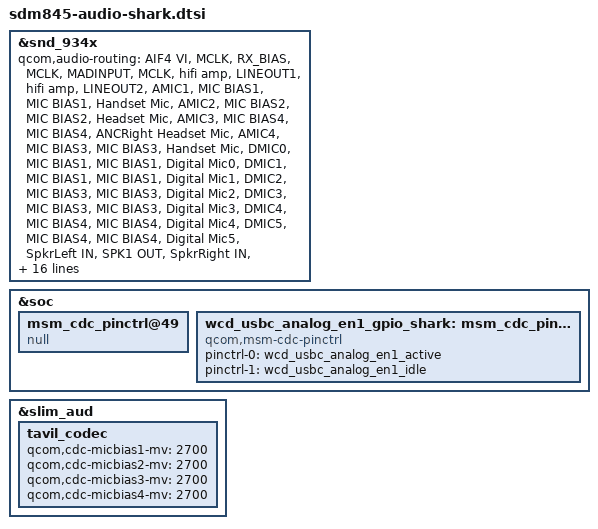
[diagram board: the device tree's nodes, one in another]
&snd_934x {
        qcom,audio-routing =
                "AIF4 VI", "MCLK",
                "RX_BIAS", "MCLK",
                "MADINPUT", "MCLK",
                "hifi amp", "LINEOUT1",
                "hifi amp", "LINEOUT2",
                "AMIC1", "MIC BIAS1",
                "MIC BIAS1", "Handset Mic",
                "AMIC2", "MIC BIAS2",
                "MIC BIAS2", "Headset Mic",
                "AMIC3", "MIC BIAS4",
                "MIC BIAS4", "ANCRight Headset Mic",
                "AMIC4", "MIC BIAS3",
                "MIC BIAS3", "Handset Mic",
                "DMIC0", "MIC BIAS1",
                "MIC BIAS1", "Digital Mic0",
                "DMIC1", "MIC BIAS1",
                "MIC BIAS1", "Digital Mic1",
                "DMIC2", "MIC BIAS3",
                "MIC BIAS3", "Digital Mic2",
                "DMIC3", "MIC BIAS3",
                "MIC BIAS3", "Digital Mic3",
                "DMIC4", "MIC BIAS4",
                "MIC BIAS4", "Digital Mic4",
                "DMIC5", "MIC BIAS4",
                "MIC BIAS4", "Digital Mic5",
                "SpkrLeft IN", "SPK1 OUT",
                "SpkrRight IN", "SPK2 OUT";

        qcom,wsa-max-devs = <0>;
        /delete-property/ qcom,hph-en0-gpio;
        /delete-property/ qcom,hph-en1-gpio;
        qcom,tas2559_smartpa;
        qcom,msm-mbhc-usbc-audio-supported = <1>;
        qcom,usbc-analog-en1-gpio = <&wcd_usbc_analog_en1_gpio_shark>;
        qcom,usbc-analog-en2-gpio = <&tlmm 91 0>;
        pinctrl-names = "aud_active", "aud_sleep",
                        "quat-mi2s-active", "quat-mi2s-sleep",
                        "quat-tdm-active", "quat-tdm-sleep";

        pinctrl-0 = <&wcd_usbc_analog_en2_active>;
        pinctrl-1 = <&wcd_usbc_analog_en2_idle>;
        pinctrl-2 = <&quat_mi2s_active &quat_mi2s_sd0_active &quat_mi2s_sd1_active>;
        pinctrl-3 = <&quat_mi2s_sleep &quat_mi2s_sd0_sleep &quat_mi2s_sd1_sleep>;
        pinctrl-4 = <&quat_tdm_active &quat_tdm_dout_active>;
        pinctrl-5 = <&quat_tdm_sleep &quat_tdm_dout_sleep>;

};

&soc {
        msm_cdc_pinctrl@49 {
                compatible = "null";
        };

        wcd_usbc_analog_en1_gpio_shark: msm_cdc_pinctrl@90 {
                compatible = "qcom,msm-cdc-pinctrl";
                pinctrl-names = "aud_active", "aud_sleep";
                pinctrl-0 = <&wcd_usbc_analog_en1_active>;
                pinctrl-1 = <&wcd_usbc_analog_en1_idle>;
        };
};

&slim_aud {
        tavil_codec {
                qcom,cdc-micbias1-mv = <2700>;
                qcom,cdc-micbias2-mv = <2700>;
                qcom,cdc-micbias3-mv = <2700>;
                qcom,cdc-micbias4-mv = <2700>;
        };
};
